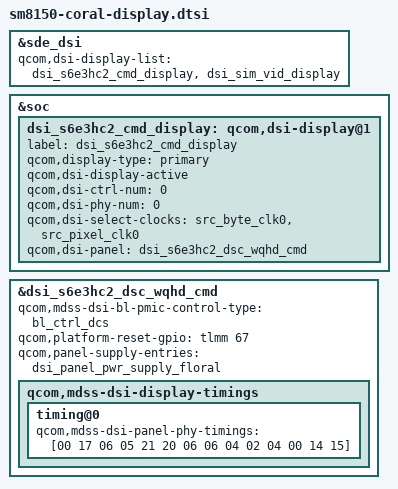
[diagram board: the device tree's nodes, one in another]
/* Copyright (c) 2018, The Linux Foundation. All rights reserved.
 *
 * This program is free software; you can redistribute it and/or modify
 * it under the terms of the GNU General Public License version 2 and
 * only version 2 as published by the Free Software Foundation.
 *
 * This program is distributed in the hope that it will be useful,
 * but WITHOUT ANY WARRANTY; without even the implied warranty of
 * MERCHANTABILITY or FITNESS FOR A PARTICULAR PURPOSE.  See the
 * GNU General Public License for more details.
 */

#include "dsi-panel-s6e3hc2-dsc-wqhd-cmd.dtsi"

&sde_dsi {
	qcom,dsi-display-list = <&dsi_s6e3hc2_cmd_display
				 &dsi_sim_vid_display>;
};

&soc {
	dsi_s6e3hc2_cmd_display: qcom,dsi-display@1 {
		label = "dsi_s6e3hc2_cmd_display";
		qcom,display-type = "primary";
		qcom,dsi-display-active;

		qcom,dsi-ctrl-num = <0>;
		qcom,dsi-phy-num = <0>;
		qcom,dsi-select-clocks = "src_byte_clk0", "src_pixel_clk0";

		qcom,dsi-panel = <&dsi_s6e3hc2_dsc_wqhd_cmd>;
	};
};

&dsi_s6e3hc2_dsc_wqhd_cmd {
	qcom,mdss-dsi-bl-pmic-control-type = "bl_ctrl_dcs";
	qcom,platform-reset-gpio = <&tlmm 67 0>;

	qcom,panel-supply-entries = <&dsi_panel_pwr_supply_floral>;

	qcom,mdss-dsi-display-timings {
		timing@0 {
			qcom,mdss-dsi-panel-phy-timings =
				[00 17 06 05 21 20 06 06 04 02 04 00 14 15];
		};
	};
};
